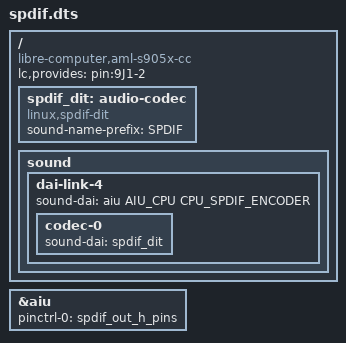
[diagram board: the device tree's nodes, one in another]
// SPDX-License-Identifier: (GPL-2.0-or-later OR MIT)
/*
 * Copyright (c) 2023 BayLibre, SAS.
 * Author: Jerome Brunet <jbrunet@baylibre.com>
 */
/*
 * Summary: spdif
 */
/dts-v1/;
/plugin/;

#include <dt-bindings/sound/meson-aiu.h>

/ {
	compatible = "libre-computer,aml-s905x-cc",
		"libretech,aml-s905x-cc",
		"libre-computer,aml-s905x-cc-v2",
		"libretech,aml-s905x-cc-v2",
		"amlogic,s905x",
		"amlogic,meson-gxl";

	/* resource-set tokens for deps/conflicts (see overlay-dependencies.md) */
	lc,provides = "pin:9J1-2";
	fragment@0 {
		target-path = "/";

		__overlay__ {
			spdif_dit: audio-codec {
				#sound-dai-cells = <0>;
				compatible = "linux,spdif-dit";
				status = "okay";
				sound-name-prefix = "SPDIF";
			};

			sound {
				dai-link-4 {
					sound-dai = <&aiu AIU_CPU CPU_SPDIF_ENCODER>;

					codec-0 {
						sound-dai = <&spdif_dit>;
					};
				};
			};
		};
	};

	fragment@1 {
		target = <&aiu>;

		__overlay__ {
			pinctrl-0 = <&spdif_out_h_pins>;
			pinctrl-names = "default";
		};
	};
};
